# CS32F036x register map
File version: 1.0
Registers are 32-bit, read-write, reset 0x0 unless marked. A register's access mark holds for its fields unless they carry their own. Offsets are from the block's base; [hi:lo] are bit positions.

## SPI1 — Serial peripheral interface
Base 0x40013000
Same registers: SPI2 0x40003800
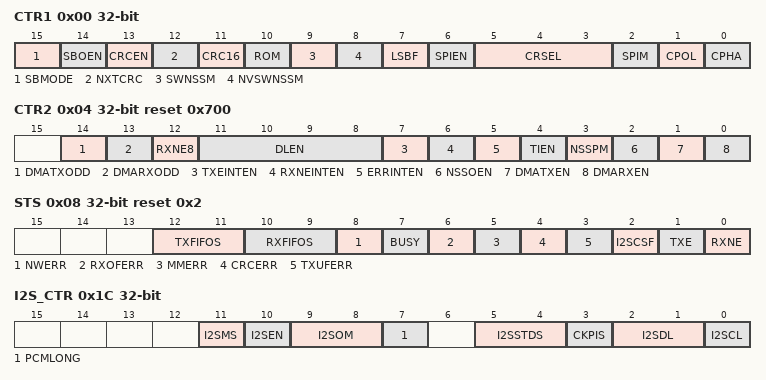
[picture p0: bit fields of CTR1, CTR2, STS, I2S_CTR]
0x00 CTR1 — control register 1
  [15] SBMODE — Single-wire bidirectional mode
  [14] SBOEN — Single-wire bidirectional output enable
  [13] CRCEN — CRC calculation enable
  [12] NXTCRC — Next CRC transfer
  [11] CRC16 — 16-bit CRC enable
  [10] ROM — Receive only mode
  [9] SWNSSM — software NSS mode
  [8] NVSWNSSM — NSS value in software NSS mode
  [7] LSBF — LSB first
  [6] SPIEN — SPI enable
  [5:3] CRSEL — Communication rate selection
  [2] SPIM — SPI mode
  [1] CPOL — Clock polarity
  [0] CPHA — Clock phase
0x04 CTR2 reset 0x700 — control register 2
  [14] DMATXODD — Number of data to transmit with DMA is odd
  [13] DMARXODD — Number of data to receive with DMA is odd
  [12] RXNE8 — RXNE generate condition selection
  [11:8] DLEN — Data length
  [7] TXEINTEN — Enable bit for transmit Buffer Empty Interrupt
  [6] RXNEINTEN — Enable bit for receive Buffer Not Empty Interrupt
  [5] ERRINTEN — Enable bit for error interrupt
  [4] TIEN — SPI TI mode enable
  [3] NSSPM — NSS pulse mode
  [2] NSSOEN — NSS output enable
  [1] DMATXEN — DMA enable for transmit
  [0] DMARXEN — DMA enable for receive
0x08 STS access per field reset 0x2 — SPI status
  [12:11] TXFIFOS ro — Transmit FIFO status
  [10:9] RXFIFOS ro — Receive FIFO status
  [8] NWERR ro — Error of SPI NSS or I2S WS
  [7] BUSY ro
  [6] RXOFERR ro — Receiver data overflow error
  [5] MMERR ro — Multi-master error
  [4] CRCERR rw — CRC error
  [3] TXUFERR ro — Transmitter data underflow error
  [2] I2SCSF ro — I2S Channel side flag
  [1] TXE ro — Transmit buffer empty
  [0] RXNE ro — Receive buffer not empty
0x0C DATA — Transfer data register
  [15:0] DATA
0x10 CRCPOLYR reset 0x7 — CRC polynomial register
  [15:0] CRCPOLYR
0x14 RCRC ro — RX CRC register
  [15:0] RCRC — Rx CRC register
0x18 TCRC ro — TX CRC register
  [15:0] TCRC — Tx CRC register
0x1C I2S_CTR — I2S control register
  [11] I2SMS — I2S mode selection
  [10] I2SEN — I2S Enable
  [9:8] I2SOM — I2S operation mode
  [7] PCMLONG — PCM long frame synchronization
  [5:4] I2SSTDS — I2S standard selection
  [3] CKPIS — clock polarity of Inactive state
  [2:1] I2SDL — I2S data length
  [0] I2SCL — I2S Channel length
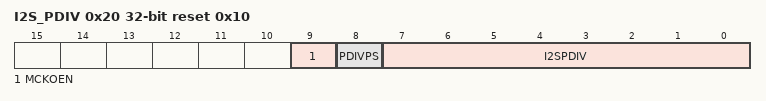
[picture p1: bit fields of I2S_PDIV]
0x20 I2S_PDIV reset 0x10 — I2S pre-divider register
  [9] MCKOEN — MCK output enable
  [8] PDIVPS — Parity selection of pre-divider
  [7:0] I2SPDIV — I2S pre-divider

## PMU — Power management unit
Base 0x40007000
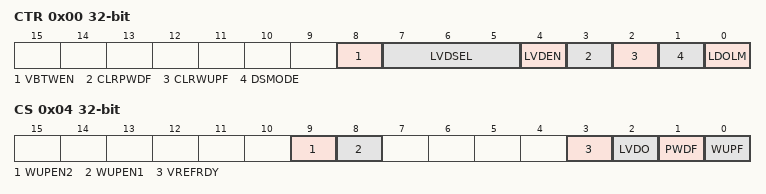
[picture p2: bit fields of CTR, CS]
0x00 CTR — control register
  [8] VBTWEN — VBAT domain write enable
  [7:5] LVDSEL — low vlotage detector threshold Selection
  [4] LVDEN — low vlotage detector Enable
  [3] CLRPWDF — Clear power down flag
  [2] CLRWUPF — Clear wakup flag
  [1] DSMODE — Deepsleep Mode or Power down selection
  [0] LDOLM — LDO low power Control
0x04 CS access per field — control/status register
  [9] WUPEN2 rw — WKUP pin2 Enable
  [8] WUPEN1 rw — WKUP pin1 Enable
  [3] VREFRDY ro — VREFINT reference voltage ready
  [2] LVDO ro — low vlotage detector Output
  [1] PWDF ro — power down flag
  [0] WUPF ro — Wakeup flag

## FWDT — Free Watchdog Timer
Base 0x40003000
0x00 CCODE wo — Control code register
  [15:0] CCODE — Control code(write only, read 0x0000)
0x04 PDIV — Pre-divider register
  [2:0] PDIV — Pre-divider
0x08 UVAL reset 0xFFF — Update register
  [11:0] UVAL — Watchdog counter update value
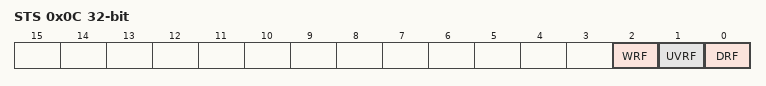
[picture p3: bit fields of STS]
0x0C STS ro — Status register
  [2] WRF — FWDT window refresh flag
  [1] UVRF — FWDT update value refresh flag
  [0] DRF — FWDT divider refresh flag
0x10 WINVAL reset 0xFFF — Window value register
  [11:0] WINVAL — FWDT window value

## WWDT — Window Watchdog Timer
Base 0x40002C00
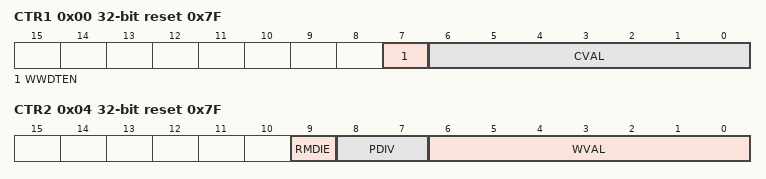
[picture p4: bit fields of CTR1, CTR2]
0x00 CTR1 reset 0x7F — Control register 1
  [7] WWDTEN — Window watchdog timer enable
  [6:0] CVAL — Counter Value
0x04 CTR2 reset 0x7F — Control register 2
  [9] RMDIE — Reminder interrupt enable
  [8:7] PDIV — Pre-divider
  [6:0] WVAL — window value
0x08 STS — Status register
  [0] RMDIF — Reminder interrupt flag
